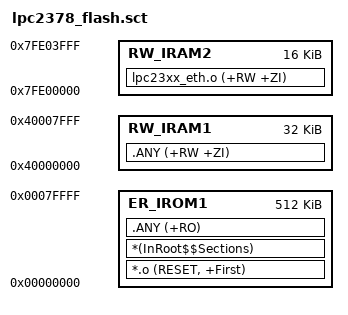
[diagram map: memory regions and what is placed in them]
;******************************************************************
;* LPC2378 linker scatter file (running code from internal FLASH) *
;******************************************************************

LR_IROM1 0x00000000 0x80000
{
   ER_IROM1 0x00000000 0x80000
   {
      *.o (RESET, +First)
      *(InRoot$$Sections)
      .ANY (+RO)
   }
   
   RW_IRAM2 0x7FE00000 0x4000
   {
      lpc23xx_eth.o (+RW +ZI)
   }
   
   RW_IRAM1 0x40000000 0x8000
   {
      .ANY (+RW +ZI)
   }
}
